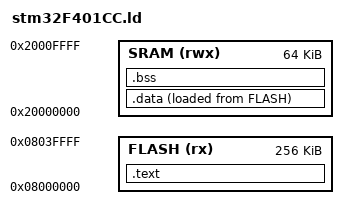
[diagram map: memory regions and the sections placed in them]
ENTRY(Reset_Handler)

MEMORY
{
    FLASH(rx) : ORIGIN = 0x08000000, LENGTH = 256k
    SRAM(rwx) : ORIGIN = 0x20000000, LENGTH = 64k
}

SECTIONS
{
    .text :
    {
        *(.isr_vector)
        *(.text)
        *(.text.*)
        *(.rodata)
        *(.rodata.*)
        . = ALIGN(4);
        _etxt = .;
    }> FLASH

    _la_data = LOADADDR(.data);

    .data :
    {
        _sdata = .;
        *(.data)
        *(.data.*)
        . = ALIGN(4);
        _edata = .;
    }> SRAM AT> FLASH

    .bss :
    {
        _sbss = .;
        __bss_start__ = _sbss;
        *(.bss)
        *(.bss.*)
        *(COMMON)
        . = ALIGN(4);
        _ebss = .;
        __bss_end__ = _ebss;
        end = .;
        __end__ = .;
    }> SRAM
}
